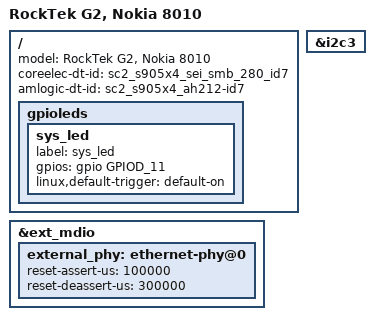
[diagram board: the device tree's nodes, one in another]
#include "sc2_s905x4_sei_smb_280_id5.dts"

/ {
	model = "RockTek G2, Nokia 8010";
	coreelec-dt-id = "sc2_s905x4_sei_smb_280_id7";
	amlogic-dt-id = "sc2_s905x4_ah212-id7";

	gpioleds {
		sys_led {
			label = "sys_led";
			gpios = <&gpio GPIOD_11 GPIO_ACTIVE_HIGH>;
			linux,default-trigger = "default-on";
		};

		/*
		net_green {
			label = "net_green";
			gpios = <&gpio GPIOD_4 GPIO_ACTIVE_LOW>;
			linux,default-trigger = "none";
		};
		*/
	};
};

&i2c3 {
	/delete-node/ bct3236@3c;
};

&ext_mdio {
	external_phy: ethernet-phy@0 {
		/* Intel XWAY PHY11G needs longer times */
		reset-assert-us = <100000>;
		reset-deassert-us = <300000>;
	};
};
